# ADuCM355 register map
Vendor: Analog Devices; Series: ADuCM355; File version: 1p0
CPU: CM3 r0p1, little endian, no MPU, no FPU, 3 interrupt priority bits
Registers are 32-bit, read-write, reset 0x0 unless marked. A register's access mark holds for its fields unless they carry their own. Offsets are from the block's base; [hi:lo] are bit positions; {n}, {i} and the like mark numbered series.

## CLKG0_OSC — Clocking
Base 0x4004C100
0x0C KEY — Key Protection for OSCCTRL
  [15:0] VALUE wo range 0x00000000..0x0000FFFF — Oscillator key
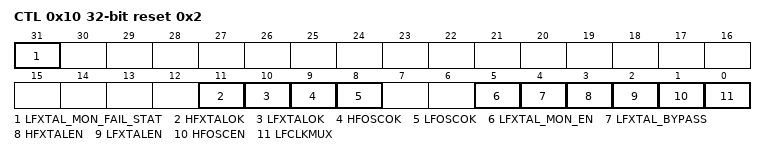
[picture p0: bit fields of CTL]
0x10 CTL reset 0x2 — Oscillator Control
  [31] LFXTAL_MON_FAIL_STAT range 0x00000000..0x00000001 — LF XTAL (crystal clock) Not Stable
  [11] HFXTALOK ro — Status of HFXTAL oscillator
  [10] LFXTALOK ro — Status of LFXTAL oscillator
  [9] HFOSCOK ro — Status of HFOSC oscillator
  [8] LFOSCOK ro — Status of LFOSC oscillator
  [5] LFXTAL_MON_EN — LFXTAL clock monitor and Clock FAIL interrupt enable
  [4] LFXTAL_BYPASS — Low frequency crystal oscillator Bypass
  [3] HFXTALEN — High frequency crystal oscillator enable
  [2] LFXTALEN — Low frequency crystal oscillator enable
  [1] HFOSCEN — High frequency internal oscillator enable
  [0] LFCLKMUX — 32 KHz clock select mux

## PMG0_TST — Power Management
Base 0x4004C200
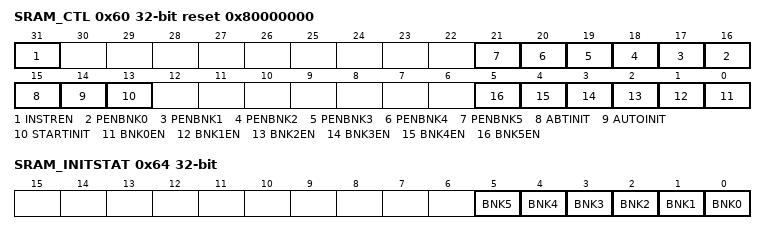
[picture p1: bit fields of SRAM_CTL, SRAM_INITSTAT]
0x60 SRAM_CTL reset 0x80000000 — Control for SRAM parity and instruction SRAM
  [31] INSTREN range 0x00000000..0x00000001 — Enables instruction SRAM
  [n+16] PENBNK{n} range 0x00000000..0x00000001 (n=0..5) — Enable parity check
  [15] ABTINIT range 0x00000000..0x00000001 — Abort current initialization. Self-cleared
  [14] AUTOINIT range 0x00000000..0x00000001 — Automatic initialization on wake up from Hibernate mode
  [13] STARTINIT range 0x00000000..0x00000001 — Write one to trigger initialization. Self-cleared
  [n] BNK{n}EN range 0x00000000..0x00000001 (n=0..5) — Enable initialization
0x64 SRAM_INITSTAT — Initialization Status Register
  [n] BNK{n} ro (n=0..5) — 0:Not initialized; 1:Initialization completed
0x68 CLR_LATCH_GPIOS 16-bit — CLEAR GPIO AFTER SHUTDOWN MODE
  [15:0] VALUE wo range 0x00000000..0x0000FFFF — Writing 0x58FA creates a pulse to clear the latches for the GPIOs
0x6C SCRPAD_IMG — SCRATCH PAD IMAGE
  [31:0] DATA range 0x00000000..0xFFFFFFFF — Anything written to this register will be saved in 3V when going to shutdown mode
0x70 SCRPAD_3V_RD — SCRATCH PAD SAVED IN BATTERY DOMAIN
  [31:0] DATA ro — Read Only register. Reading the scratch pad stored in shutdown mode

## CLKG0_CLK — Clocking
Base 0x4004C300
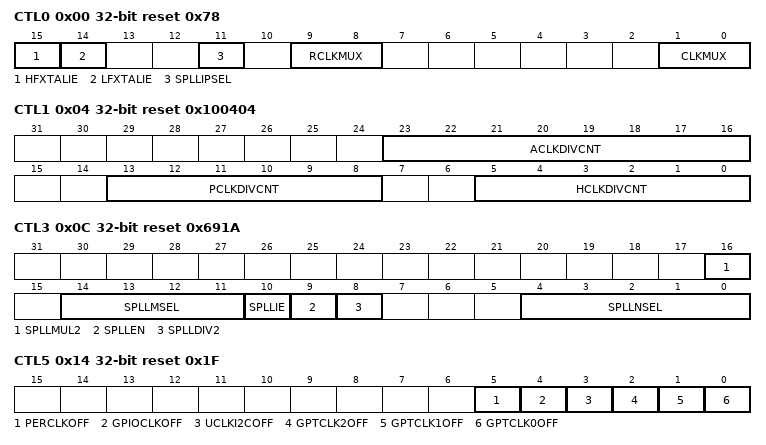
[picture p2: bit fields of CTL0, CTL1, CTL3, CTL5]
0x00 CTL0 reset 0x78 — Misc clock settings
  [15] HFXTALIE — High frequency crystal interrupt enable
  [14] LFXTALIE — Low frequency crystal interrupt enable
  [11] SPLLIPSEL — SPLL source select mux
  [9:8] RCLKMUX — Flash reference clock and HPBUCK clock source mux
  [1:0] CLKMUX — Clock mux select
0x04 CTL1 reset 0x100404 — Clock dividers
  [23:16] ACLKDIVCNT range 0x00000000..0x000000FF — ACLK Divide Count.
  [13:8] PCLKDIVCNT range 0x00000000..0x0000003F — PCLK divide count
  [5:0] HCLKDIVCNT range 0x00000000..0x0000003F — HCLK divide count
0x0C CTL3 reset 0x691A — System PLL
  [16] SPLLMUL2 — system PLL multiply by 2
  [14:11] SPLLMSEL range 0x00000000..0x0000000F — System PLL M Divider
  [10] SPLLIE — System PLL interrupt enable
  [9] SPLLEN — System PLL enable
  [8] SPLLDIV2 — System PLL division by 2
  [4:0] SPLLNSEL range 0x00000000..0x0000001F — System PLL N multiplier
0x14 CTL5 reset 0x1F — User clock gating control
  [5] PERCLKOFF range 0x00000000..0x00000001 — This bit is used to disable all clocks connected to all peripherals
  [4] GPIOCLKOFF — GPIO clock control
  [3] UCLKI2COFF — I2C clock user control
  [2] GPTCLK2OFF — GP timer 2 user control
  [1] GPTCLK1OFF — GP timer 1 user control
  [0] GPTCLK0OFF — GP timer 0 user control
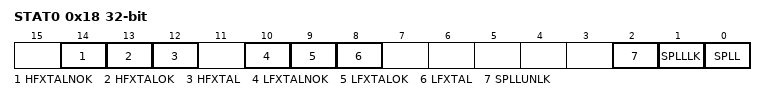
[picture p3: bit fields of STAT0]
0x18 STAT0 — Clocking status
  [14] HFXTALNOK — HF crystal not stable
  [13] HFXTALOK — HF crystal stable
  [12] HFXTAL ro — HF crystal status
  [10] LFXTALNOK — LF crystal not stable
  [9] LFXTALOK — LF crystal stable
  [8] LFXTAL ro — LF crystal status
  [2] SPLLUNLK — System PLL unlock
  [1] SPLLLK — System PLL lock
  [0] SPLL ro — System PLL status
